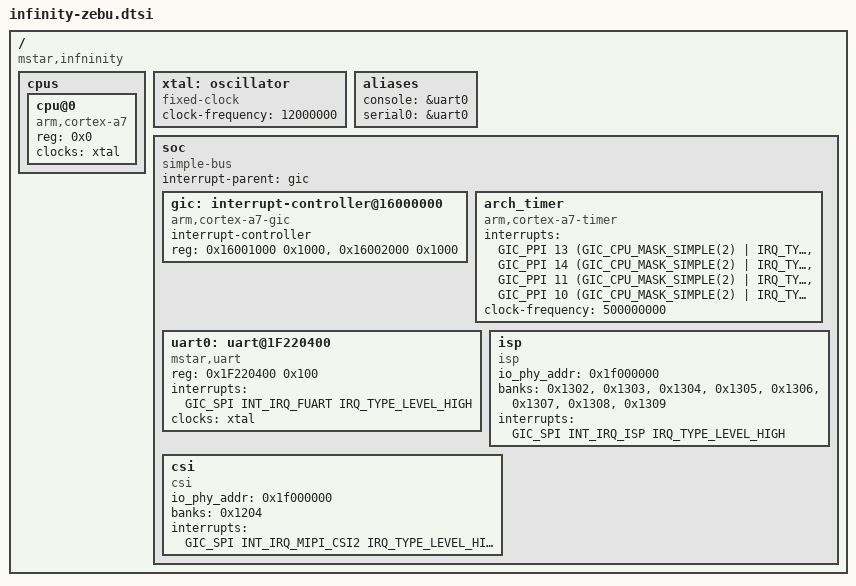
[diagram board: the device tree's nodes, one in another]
/*
 * Copyright (c) 2014 MundoReader S.L.
 * Author: Matthias Brugger <matthias.bgg@gmail.com>
 *
 * This program is free software; you can redistribute it and/or modify
 * it under the terms of the GNU General Public License as published by
 * the Free Software Foundation; either version 2 of the License, or
 * (at your option) any later version.
 *
 * This program is distributed in the hope that it will be useful,
 * but WITHOUT ANY WARRANTY; without even the implied warranty of
 * MERCHANTABILITY or FITNESS FOR A PARTICULAR PURPOSE.  See the
 * GNU General Public License for more details.
 */

#include <../../../../drivers/mstar/include/infinity/irqs.h>
#include <dt-bindings/interrupt-controller/irq.h>
#include <dt-bindings/interrupt-controller/arm-gic.h>
#include "skeleton.dtsi"

/ {
    compatible = "mstar,infninity";
  
    cpus {
        #address-cells = <1>;
        #size-cells = <0>;

        cpu@0 {
            device_type = "cpu";
            compatible = "arm,cortex-a7";
            reg = <0x0>;
            clocks = <&xtal>;
        };
    };
    
    xtal: oscillator {
		compatible = "fixed-clock";
		#clock-cells = <0>;
		clock-frequency = <12000000>;
	};
	
  	aliases {
    	console = &uart0;
    	serial0 = &uart0;
	}; 
    
   
    soc {    
        compatible = "simple-bus";   
        interrupt-parent = <&gic>;
        #address-cells = <1>;
        #size-cells = <1>;
        ranges = <0 0 0xFFFFFFFF>;
        

        gic: interrupt-controller@16000000 {
            compatible = "arm,cortex-a7-gic";
            #interrupt-cells = <3>;
            #address-cells = <1>;
            #size-cells = <1>;
            interrupt-controller;
            reg = <0x16001000 0x1000>,
                  <0x16002000 0x1000>;
        };

        arch_timer {
            compatible = "arm,cortex-a7-timer", "arm,armv7-timer";
            interrupts = <GIC_PPI 13 (GIC_CPU_MASK_SIMPLE(2) | IRQ_TYPE_LEVEL_LOW)>,
                         <GIC_PPI 14 (GIC_CPU_MASK_SIMPLE(2) | IRQ_TYPE_LEVEL_LOW)>,
                         <GIC_PPI 11 (GIC_CPU_MASK_SIMPLE(2) | IRQ_TYPE_LEVEL_LOW)>,
                         <GIC_PPI 10 (GIC_CPU_MASK_SIMPLE(2) | IRQ_TYPE_LEVEL_LOW)>;
            clock-frequency = <500000000>;  /* arch_timer must use clock-frequency*/
        };
        
/*       
        timer_clockevent: timer@1F006040 {
			compatible = "mstar,piu-clockevent";
			reg = <0x1F006040 0x100>;
			interrupts = <GIC_SPI INT_FIQ_TIMER_0 IRQ_TYPE_LEVEL_HIGH>;
			clocks = <&xtal>;
		};
*/
		uart0: uart@1F220400 {
			compatible = "mstar,uart";
			reg = <0x1F220400 0x100>;
			interrupts= <GIC_SPI INT_IRQ_FUART IRQ_TYPE_LEVEL_HIGH>;
			status = "ok";
            clocks = <&xtal>;
		}; 
		
		isp: isp {
            compatible = "isp";
            io_phy_addr = <0x1f000000>;
            banks = <0x1302>,<0x1303>,<0x1304>,<0x1305>,<0x1306>,<0x1307>,<0x1308>,<0x1309>;
            interrupts=  <GIC_SPI INT_IRQ_ISP  IRQ_TYPE_LEVEL_HIGH>;
        };
        
        csi: csi {
            compatible = "csi";
            io_phy_addr = <0x1f000000>;
            banks = <0x1204>;
            interrupts=  <GIC_SPI INT_IRQ_MIPI_CSI2 IRQ_TYPE_LEVEL_HIGH>;
        };
    };
};
